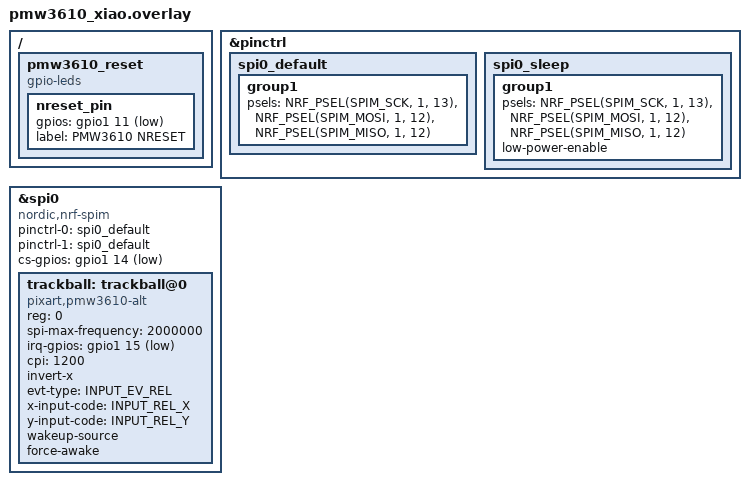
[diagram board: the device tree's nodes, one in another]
#include "pmw3610_xiao.dtsi"

/ {
    pmw3610_reset: pmw3610_reset {
        compatible = "gpio-leds";
        nreset_pin: nreset_pin {
            gpios = <&gpio1 11 GPIO_ACTIVE_LOW>;
            label = "PMW3610 NRESET";
        };
    };
};

&pinctrl {
    spi0_default: spi0_default {
        group1 {
            psels = <NRF_PSEL(SPIM_SCK, 1, 13)>,
                <NRF_PSEL(SPIM_MOSI, 1, 12)>,
                <NRF_PSEL(SPIM_MISO, 1, 12)>;
        };
    };

    spi0_sleep: spi0_sleep {
        group1 {
            psels = <NRF_PSEL(SPIM_SCK, 1, 13)>,
                <NRF_PSEL(SPIM_MOSI, 1, 12)>,
                <NRF_PSEL(SPIM_MISO, 1, 12)>;
            low-power-enable;
        };
    };
};

#include <zephyr/dt-bindings/input/input-event-codes.h>

&spi0 {
    status = "okay";
    compatible = "nordic,nrf-spim";
    pinctrl-0 = <&spi0_default>;
    pinctrl-1 = <&spi0_default>;
    pinctrl-names = "default", "sleep";
    cs-gpios = <&gpio1 14 GPIO_ACTIVE_LOW>;

    trackball: trackball@0 {
        status = "okay";
        compatible = "pixart,pmw3610-alt";
        reg = <0>;
        spi-max-frequency = <2000000>;
        irq-gpios = <&gpio1 15 (GPIO_ACTIVE_LOW | GPIO_PULL_UP)>;
        cpi = <1200>;
        // swap-xy;
        invert-x;
        //invert-y; /* optional */
        evt-type = <INPUT_EV_REL>;
        x-input-code = <INPUT_REL_X>;
        y-input-code = <INPUT_REL_Y>;

        /* Cấp nguồn từ 3.3V cố định nên sensor vẫn có điện trong sleep.
           Thêm wakeup-source để IRQ pin có thể wakeup board khi trackball di chuyển. */
        wakeup-source;

        force-awake; /* Giữ sensor ở chế độ awake khi ZMK active,
                        tránh sensor rơi vào downshift mode sau wakeup */

        // force-awake-4ms-mode; /* optional */
        /* while force-awake is acitvated, enable this mode to force sampling per 
           4ms, where the default sampling rate is 8ms. */
        /* NOTE: apply this mode if you need 250Hz with direct USB connection. */
    };
};
